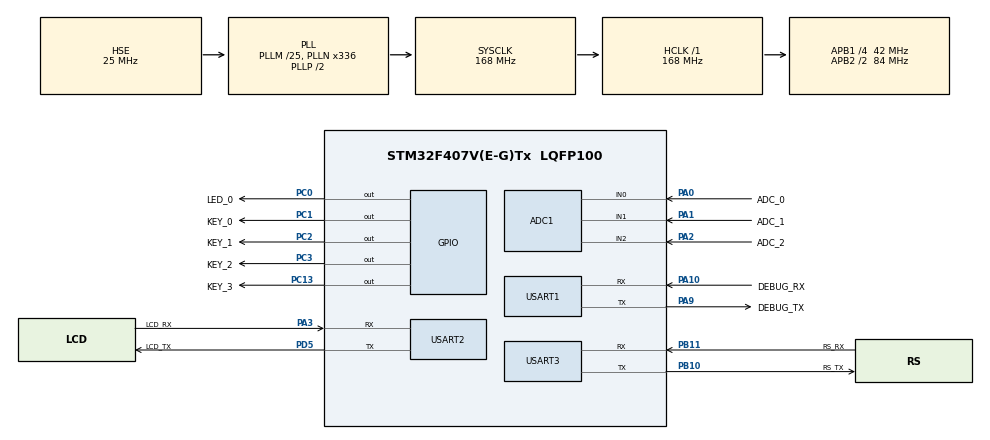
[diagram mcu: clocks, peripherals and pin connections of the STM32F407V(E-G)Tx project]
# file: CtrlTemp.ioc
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ADC1.Channel-0\#ChannelRegularConversion=ADC_CHANNEL_0
ADC1.InjNumberOfConversion=0
ADC1.NbrOfConversionFlag=1
ADC1.Rank-0\#ChannelRegularConversion=1
ADC1.SamplingTime-0\#ChannelRegularConversion=ADC_SAMPLETIME_3CYCLES
ADC1.master=1
Mcu.Family=STM32F4
Mcu.Name=STM32F407V(E-G)Tx
Mcu.Package=LQFP100
NVIC.ADC_IRQn=true\:0\:0\:false\:false\:false\:false\:true\:false
NVIC.PriorityGroup=NVIC_PRIORITYGROUP_4
NVIC.USART1_IRQn=true\:0\:0\:false\:false\:false\:false\:true\:false
NVIC.USART2_IRQn=true\:0\:0\:false\:false\:false\:false\:true\:false
NVIC.USART3_IRQn=true\:0\:0\:false\:true\:false\:1\:false\:true\:false
PA0-WKUP.GPIO_Label=ADC_0
PA0-WKUP.Signal=ADCx_IN0
PA1.GPIO_Label=ADC_1
PA1.Signal=ADCx_IN1
PA10.GPIO_Label=DEBUG_RX
PA10.Mode=Asynchronous
PA10.Signal=USART1_RX
PA13.Mode=Serial_Wire
PA13.Signal=SYS_JTMS-SWDIO
PA14.Mode=Serial_Wire
PA14.Signal=SYS_JTCK-SWCLK
PA2.GPIO_Label=ADC_2
PA2.Signal=ADCx_IN2
PA3.GPIO_Label=LCD_RX
PA3.Mode=Asynchronous
PA3.Signal=USART2_RX
PA9.GPIO_Label=DEBUG_TX
PA9.Mode=Asynchronous
PA9.Signal=USART1_TX
PB10.GPIO_Label=RS_TX
PB10.Mode=Asynchronous
PB10.Signal=USART3_TX
PB11.GPIO_Label=RS_RX
PB11.Mode=Asynchronous
PB11.Signal=USART3_RX
PC0.GPIO_Label=LED_0
PC0.Signal=GPIO_Output
PC1.GPIO_Label=KEY_0
PC1.Signal=GPIO_Output
PC13-ANTI_TAMP.GPIO_Label=KEY_3
PC13-ANTI_TAMP.Signal=GPIO_Output
PC2.GPIO_Label=KEY_1
PC2.Signal=GPIO_Output
PC3.GPIO_Label=KEY_2
PC3.Signal=GPIO_Output
PD5.GPIO_Label=LCD_TX
PD5.Mode=Asynchronous
PD5.Signal=USART2_TX
PH0-OSC_IN.Mode=HSE-External-Oscillator
PH0-OSC_IN.Signal=RCC_OSC_IN
PH1-OSC_OUT.Mode=HSE-External-Oscillator
PH1-OSC_OUT.Signal=RCC_OSC_OUT
ProjectManager.HeapSize=0x200
ProjectManager.StackSize=0x400
ProjectManager.TargetToolchain=MDK-ARM V5.27
RCC.48MHZClocksFreq_Value=84000000
RCC.AHBFreq_Value=168000000
RCC.APB1CLKDivider=RCC_HCLK_DIV4
RCC.APB1Freq_Value=42000000
RCC.APB1TimFreq_Value=84000000
RCC.APB2CLKDivider=RCC_HCLK_DIV2
RCC.APB2Freq_Value=84000000
RCC.APB2TimFreq_Value=168000000
RCC.CortexFreq_Value=168000000
RCC.HCLKFreq_Value=168000000
RCC.HSE_VALUE=25000000
RCC.HSI_VALUE=16000000
RCC.LSE_VALUE=32768
RCC.PLLM=25
RCC.PLLN=336
RCC.PLLSourceVirtual=RCC_PLLSOURCE_HSE
RCC.SYSCLKFreq_VALUE=168000000
RCC.SYSCLKSource=RCC_SYSCLKSOURCE_PLLCLK
RCC.VCOOutputFreq_Value=336000000
RealThread.RT-Thread.3.1.3.RTAaThreadCcRTOSJjkernel=true
RealThread.RT-Thread.3.1.3.RTAaThreadCcRTOSJjshell=true
RealThread.RT-Thread.3.1.3.RT_DEBUG=1
RealThread.RT-Thread.3.1.3.RT_NAME_MAX=16
RealThread.RT-Thread.3.1.3.RT_USING_EVENT=1
RealThread.RT-Thread.3.1.3.RT_USING_HEAP=1
RealThread.RT-Thread.3.1.3.RT_USING_HOOK=1
RealThread.RT-Thread.3.1.3.RT_USING_IDLE_HOOK=1
RealThread.RT-Thread.3.1.3.RT_USING_MAILBOX=1
RealThread.RT-Thread.3.1.3.RT_USING_MESSAGEQUEUE=1
RealThread.RT-Thread.3.1.3.RT_USING_MUTEX=1
RealThread.RT-Thread.3.1.3.RT_USING_TINY_SIZE=1
SH.ADCx_IN0.0=ADC1_IN0,IN0
SH.ADCx_IN1.0=ADC1_IN1,IN1
SH.ADCx_IN2.0=ADC1_IN2,IN2
USART1.VirtualMode=VM_ASYNC
USART2.VirtualMode=VM_ASYNC
USART3.VirtualMode=VM_ASYNC
VP_RealThread.RT-Thread_VS_RTOSJjRTAaThread_3.1.3.Mode=RTOSJjRTAaThread
board=custom

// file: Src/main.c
/* USER CODE BEGIN Header */
/**
  ******************************************************************************
  * @file           : main.c
  * @brief          : Main program body
  ******************************************************************************
  * @attention
  *
  * <h2><center>&copy; Copyright (c) 2020 STMicroelectronics.
  * All rights reserved.</center></h2>
  *
  * This software component is licensed by ST under BSD 3-Clause license,
  * the "License"; You may not use this file except in compliance with the
  * License. You may obtain a copy of the License at:
  *                        opensource.org/licenses/BSD-3-Clause
  *
  ******************************************************************************
  */
/* USER CODE END Header */
#include "main.h"
#include "adc.h"
#include "usart.h"
#include "gpio.h"

/* USER CODE BEGIN Includes */
#include "rtthread.h"
/* USER CODE END Includes */

void SystemClock_Config(void);
static void MX_NVIC_Init(void);

int main(void)
{

  /* MCU Configuration--------------------------------------------------------*/

  /* Reset of all peripherals, Initializes the Flash interface and the Systick. */
  HAL_Init();

  /* USER CODE BEGIN Init */
#DEFINE.........JDKSALK
  /* USER CODE END Init */

  /* Configure the system clock */
  SystemClock_Config();

  /* Initialize all configured peripherals */
  MX_GPIO_Init();
  MX_ADC1_Init();
  MX_USART1_UART_Init();
  MX_USART2_UART_Init();
  MX_USART3_UART_Init();

  /* Initialize interrupts */
  MX_NVIC_Init();

  /* Infinite loop */
  while (1)
  {
  }
}

void SystemClock_Config(void)
{
  RCC_OscInitTypeDef RCC_OscInitStruct = {0};
  RCC_ClkInitTypeDef RCC_ClkInitStruct = {0};

  /** Configure the main internal regulator output voltage
  */
  __HAL_RCC_PWR_CLK_ENABLE();
  __HAL_PWR_VOLTAGESCALING_CONFIG(PWR_REGULATOR_VOLTAGE_SCALE1);
  /** Initializes the RCC Oscillators according to the specified parameters
  * in the RCC_OscInitTypeDef structure.
  */
  RCC_OscInitStruct.OscillatorType = RCC_OSCILLATORTYPE_HSE;
  RCC_OscInitStruct.HSEState = RCC_HSE_ON;
  RCC_OscInitStruct.PLL.PLLState = RCC_PLL_ON;
  RCC_OscInitStruct.PLL.PLLSource = RCC_PLLSOURCE_HSE;
  RCC_OscInitStruct.PLL.PLLM = 25;
  RCC_OscInitStruct.PLL.PLLN = 336;
  RCC_OscInitStruct.PLL.PLLP = RCC_PLLP_DIV2;
  RCC_OscInitStruct.PLL.PLLQ = 4;
  if (HAL_RCC_OscConfig(&RCC_OscInitStruct) != HAL_OK)
  {
    Error_Handler();
  }
  /** Initializes the CPU, AHB and APB buses clocks
  */
  RCC_ClkInitStruct.ClockType = RCC_CLOCKTYPE_HCLK|RCC_CLOCKTYPE_SYSCLK
                              |RCC_CLOCKTYPE_PCLK1|RCC_CLOCKTYPE_PCLK2;
  RCC_ClkInitStruct.SYSCLKSource = RCC_SYSCLKSOURCE_PLLCLK;
  RCC_ClkInitStruct.AHBCLKDivider = RCC_SYSCLK_DIV1;
  RCC_ClkInitStruct.APB1CLKDivider = RCC_HCLK_DIV4;
  RCC_ClkInitStruct.APB2CLKDivider = RCC_HCLK_DIV2;

  if (HAL_RCC_ClockConfig(&RCC_ClkInitStruct, FLASH_LATENCY_5) != HAL_OK)
  {
    Error_Handler();
  }
}

/**
  * @brief NVIC Configuration.
  * @retval None
  */
static void MX_NVIC_Init(void)
{
  /* USART3_IRQn interrupt configuration */
  HAL_NVIC_SetPriority(USART3_IRQn, 0, 0);
  HAL_NVIC_EnableIRQ(USART3_IRQn);
}

void Error_Handler(void)
{
}

/************************ (C) COPYRIGHT STMicroelectronics *****END OF FILE****/
